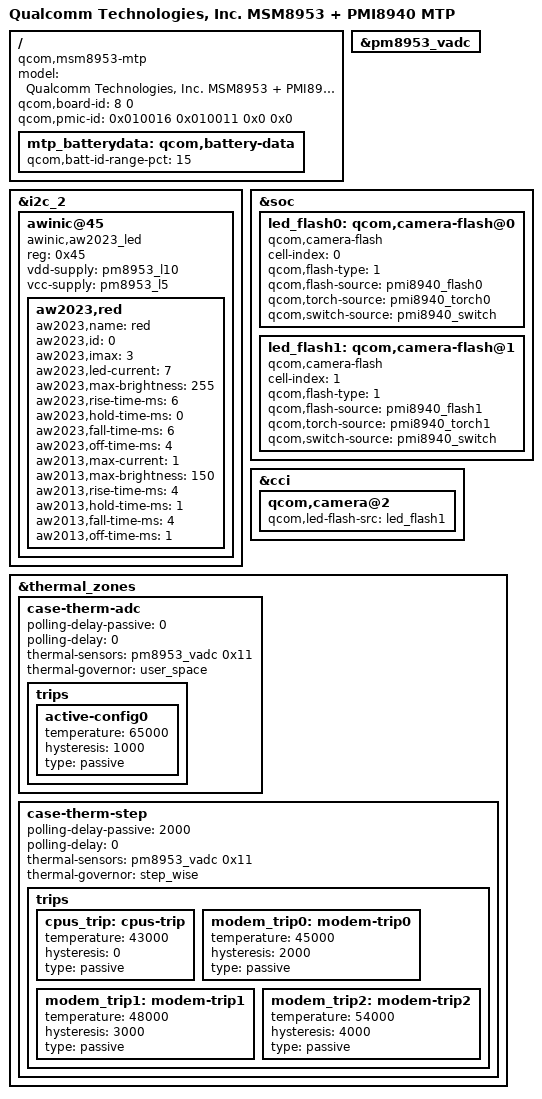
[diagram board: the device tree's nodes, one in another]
/*
 * Copyright (c) 2016-2017, The Linux Foundation. All rights reserved.
 * Copyright (C) 2019 XiaoMi, Inc.
 *
 * This program is free software; you can redistribute it and/or modify
 * it under the terms of the GNU General Public License version 2 and
 * only version 2 as published by the Free Software Foundation.
 *
 * This program is distributed in the hope that it will be useful,
 * but WITHOUT ANY WARRANTY; without even the implied warranty of
 * MERCHANTABILITY or FITNESS FOR A PARTICULAR PURPOSE.  See the
 * GNU General Public License for more details.
 */

/dts-v1/;

#include "msm8953.dtsi"
#include "pmi8940.dtsi"
#include "msm8953-mtp.dtsi"
#include "msm8953-pmi8940.dtsi"

/ {
	model = "Qualcomm Technologies, Inc. MSM8953 + PMI8940 MTP";
	compatible = "qcom,msm8953-mtp", "qcom,msm8953", "qcom,mtp";
	qcom,board-id= <8 0>;
	qcom,pmic-id = <0x010016 0x010011 0x0 0x0>;
};

/{
	mtp_batterydata: qcom,battery-data {
		qcom,batt-id-range-pct = <15>;
        	#include "batterydata-coslight-3000mah.dtsi"
        	#include "batterydata-sunwoda-3000mah.dtsi"
        	#include "batterydata-share-3000mah.dtsi"
	};
};

&i2c_2 { /* BLSP1 QUP2 */
	/delete-node/ adv7533@39;
};

&pm8953_vadc {
	/delete-node/ chan@13;
};

&i2c_2 {//E6
	status = "ok";
	awinic@45 { // Breath Light-Driven
		compatible = "awinic,aw2023_led";
		reg = <0x45>;
		vdd-supply = <&pm8953_l10>;
		vcc-supply = <&pm8953_l5>;

		aw2023,red {
			aw2023,name = "red";
			aw2023,id = <0>;
			aw2023,imax = <3>;
			aw2023,led-current = <7>;
			aw2023,max-brightness = <255>;
			aw2023,rise-time-ms = <6>;
			aw2023,hold-time-ms = <0>;
			aw2023,fall-time-ms = <6>;
			aw2023,off-time-ms = <4>;

			aw2013,max-current = <1>;
			aw2013,max-brightness = <150>;
			aw2013,rise-time-ms = <4>;
			aw2013,hold-time-ms = <1>;
			aw2013,fall-time-ms = <4>;
			aw2013,off-time-ms = <1>;
		};
	};
};

// Flash nodes
&soc {
	led_flash0: qcom,camera-flash@0 {
		cell-index = <0>;
		compatible = "qcom,camera-flash";
		qcom,flash-type = <1>;
		qcom,flash-source = <&pmi8940_flash0>;
		qcom,torch-source = <&pmi8940_torch0>;
		qcom,switch-source = <&pmi8940_switch>;
	};
	led_flash1: qcom,camera-flash@1 {
		cell-index = <1>;
		compatible = "qcom,camera-flash";
		qcom,flash-type = <1>;
		qcom,flash-source = <&pmi8940_flash1>;
		qcom,torch-source = <&pmi8940_torch1>;
		qcom,switch-source = <&pmi8940_switch>;
	};

};

&cci {
	qcom,camera@2 {
		qcom,led-flash-src = <&led_flash1>;
	};
};

// Thermal nodes
&thermal_zones {
	case-therm-adc {
		polling-delay-passive = <0>;
		polling-delay = <0>;
		thermal-sensors = <&pm8953_vadc 0x11>;
		thermal-governor = "user_space";

		trips {
			active-config0 {
				temperature = <65000>;
				hysteresis = <1000>;
				type = "passive";
			};
		};
	};
	case-therm-step {
		polling-delay-passive = <2000>;
		polling-delay = <0>;
		thermal-sensors = <&pm8953_vadc 0x11>;
		thermal-governor = "step_wise";

		trips {
			cpus_trip: cpus-trip {
				temperature = <43000>;
				hysteresis = <0>;
				type = "passive";
			};
			modem_trip0: modem-trip0 {
				temperature = <45000>;
				hysteresis = <2000>;
				type = "passive";
			};
			modem_trip1: modem-trip1 {
				temperature = <48000>;
				hysteresis = <3000>;
				type = "passive";
			};
			modem_trip2: modem-trip2 {
				temperature = <54000>;
				hysteresis = <4000>;
				type = "passive";
			};
		};
	};
};

#include "xiaomi/ysl.dtsi"
